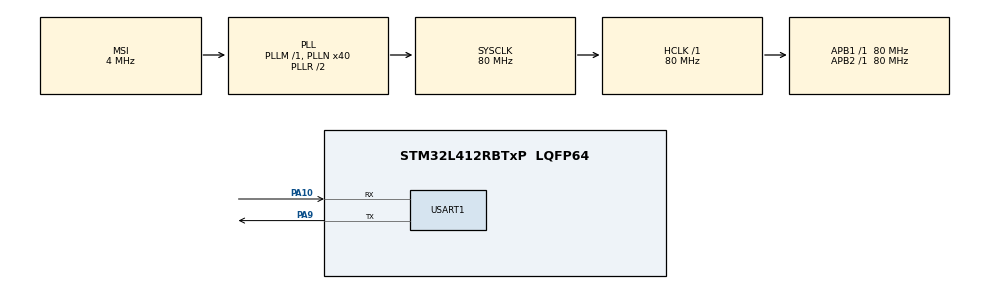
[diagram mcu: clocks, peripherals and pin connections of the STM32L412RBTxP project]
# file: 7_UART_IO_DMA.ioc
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Dma.Request0=USART1_RX
Dma.USART1_RX.0.Direction=DMA_PERIPH_TO_MEMORY
Dma.USART1_RX.0.Instance=DMA1_Channel5
Dma.USART1_RX.0.MemDataAlignment=DMA_MDATAALIGN_BYTE
Dma.USART1_RX.0.MemInc=DMA_MINC_ENABLE
Dma.USART1_RX.0.Mode=DMA_CIRCULAR
Dma.USART1_RX.0.PeriphDataAlignment=DMA_PDATAALIGN_BYTE
Dma.USART1_RX.0.PeriphInc=DMA_PINC_DISABLE
Dma.USART1_RX.0.Priority=DMA_PRIORITY_LOW
Mcu.Family=STM32L4
Mcu.Name=STM32L412RBTxP
Mcu.Package=LQFP64
NVIC.DMA1_Channel5_IRQn=true\:0\:0\:false\:false\:true\:false\:true
NVIC.PriorityGroup=NVIC_PRIORITYGROUP_4
NVIC.USART1_IRQn=true\:0\:0\:false\:false\:true\:true\:true
PA10.Mode=Asynchronous
PA10.Signal=USART1_RX
PA9.Mode=Asynchronous
PA9.Signal=USART1_TX
ProjectManager.HeapSize=0x200
ProjectManager.StackSize=0x400
ProjectManager.TargetToolchain=STM32CubeIDE
RCC.ADCFreq_Value=80000000
RCC.AHBFreq_Value=80000000
RCC.APB1Freq_Value=80000000
RCC.APB1TimFreq_Value=80000000
RCC.APB2Freq_Value=80000000
RCC.APB2TimFreq_Value=80000000
RCC.CortexFreq_Value=80000000
RCC.HCLKFreq_Value=80000000
RCC.HSE_VALUE=8000000
RCC.HSI48_VALUE=48000000
RCC.HSI_VALUE=16000000
RCC.LSE_VALUE=32768
RCC.MSI_VALUE=4000000
RCC.PLLN=40
RCC.SYSCLKFreq_VALUE=80000000
RCC.SYSCLKSource=RCC_SYSCLKSOURCE_PLLCLK
RCC.USBFreq_Value=4000000
RCC.VCOOutputFreq_Value=160000000
USART1.VirtualMode-Asynchronous=VM_ASYNC
board=custom

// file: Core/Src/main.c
/* USER CODE BEGIN Header */
/**
  ******************************************************************************
  * @file           : main.c
  * @brief          : Main program body
  ******************************************************************************
  * @attention
  *
  * <h2><center>&copy; Copyright (c) 2021 STMicroelectronics.
  * All rights reserved.</center></h2>
  *
  * This software component is licensed by ST under BSD 3-Clause license,
  * the "License"; You may not use this file except in compliance with the
  * License. You may obtain a copy of the License at:
  *                        opensource.org/licenses/BSD-3-Clause
  *
  ******************************************************************************
  */
/* USER CODE END Header */
#include "main.h"
#include "dma.h"
#include "usart.h"
#include "gpio.h"

/* USER CODE BEGIN Includes */
#include <string.h>
/* USER CODE END Includes */

/* USER CODE BEGIN PV */
#if 0
#define DMA_BUF_SIZE 100
uint8_t rx_dma_buf[DMA_BUF_SIZE];
#define get_dma_data_length() huart1.hdmarx->Instance->CNDTR
#define get_dma_total_size()  huart1.RxXferSize
#else
uint8_t rxBuffer[10];

#endif
/* USER CODE END PV */

void SystemClock_Config(void);

/* USER CODE BEGIN 0 */
#if 0
void uart_rx_dma_handler(){
    /* buffer index*/
    static uint32_t old_pos=0;
    uint32_t pos;

    /* trans buffer from dma buffer*/
    uint8_t rx_buf[DMA_BUF_SIZE];
    uint32_t rx_size = 0;

    /*trans variable*/
    uint8_t ch;
    uint8_t i;

    /*find current index in buffer*/
    pos = get_dma_total_size() - get_dma_data_length();

    if(pos != old_pos)
    {
        if(pos > old_pos)
        {
            /* get data from dma buf*/
            memcpy(rx_buf, &rx_dma_buf[old_pos], pos - old_pos);
            rx_size += pos - old_pos;
        }
        else
        {
            /* Overflow */
            /* fisrt get data until end index */
            memcpy(rx_buf, &rx_dma_buf[old_pos], get_dma_total_size() - old_pos);
            rx_size += get_dma_total_size() - old_pos;

            /* check cur and get data until cur index*/
            if(pos > 0)
            {
                memcpy(&rx_buf[get_dma_total_size() - old_pos], &rx_dma_buf[0], pos);
                rx_size += pos;
            }
        }

        old_pos = pos;
        if(rx_size > 0)
        {
            for(i = 0;i<rx_size;i++)
            {
                ch = rx_buf[i];
                //printf("%02X", ch);
                HAL_UART_Transmit(&huart1, &ch, sizeof(uint8_t), 1000);
            }
            //printf("\n\r");
        }
    }
}
#else
void HAL_UART_RxCpltCallback(UART_HandleTypeDef *huart)
{
  HAL_UART_Transmit(&huart1, rxBuffer, 10, 0xFFFF);
}

#endif
/* USER CODE END 0 */

int main(void)
{

  /* MCU Configuration--------------------------------------------------------*/

  /* Reset of all peripherals, Initializes the Flash interface and the Systick. */
  HAL_Init();

  /* Configure the system clock */
  SystemClock_Config();

  /* Initialize all configured peripherals */
  MX_GPIO_Init();
  MX_DMA_Init();
  MX_USART1_UART_Init();
  /* USER CODE BEGIN 2 */
#if 0
  HAL_UART_Receive_DMA(&huart1, rx_dma_buf, DMA_BUF_SIZE);
#else
  HAL_UART_Receive_DMA(&huart1, rxBuffer, 10);
#endif
  /* USER CODE END 2 */

  /* Infinite loop */
  /* USER CODE BEGIN WHILE */
  while (1)
  {
#if 0
    uart_rx_dma_handler();
#else

#endif
    /* USER CODE END WHILE */

  }
}

void SystemClock_Config(void)
{
  RCC_OscInitTypeDef RCC_OscInitStruct = {0};
  RCC_ClkInitTypeDef RCC_ClkInitStruct = {0};
  RCC_PeriphCLKInitTypeDef PeriphClkInit = {0};

  /** Configure the main internal regulator output voltage
  */
  if (HAL_PWREx_ControlVoltageScaling(PWR_REGULATOR_VOLTAGE_SCALE1) != HAL_OK)
  {
    Error_Handler();
  }
  /** Initializes the RCC Oscillators according to the specified parameters
  * in the RCC_OscInitTypeDef structure.
  */
  RCC_OscInitStruct.OscillatorType = RCC_OSCILLATORTYPE_MSI;
  RCC_OscInitStruct.MSIState = RCC_MSI_ON;
  RCC_OscInitStruct.MSICalibrationValue = 0;
  RCC_OscInitStruct.MSIClockRange = RCC_MSIRANGE_6;
  RCC_OscInitStruct.PLL.PLLState = RCC_PLL_ON;
  RCC_OscInitStruct.PLL.PLLSource = RCC_PLLSOURCE_MSI;
  RCC_OscInitStruct.PLL.PLLM = 1;
  RCC_OscInitStruct.PLL.PLLN = 40;
  RCC_OscInitStruct.PLL.PLLQ = RCC_PLLQ_DIV2;
  RCC_OscInitStruct.PLL.PLLR = RCC_PLLR_DIV2;
  if (HAL_RCC_OscConfig(&RCC_OscInitStruct) != HAL_OK)
  {
    Error_Handler();
  }
  /** Initializes the CPU, AHB and APB buses clocks
  */
  RCC_ClkInitStruct.ClockType = RCC_CLOCKTYPE_HCLK|RCC_CLOCKTYPE_SYSCLK
                              |RCC_CLOCKTYPE_PCLK1|RCC_CLOCKTYPE_PCLK2;
  RCC_ClkInitStruct.SYSCLKSource = RCC_SYSCLKSOURCE_PLLCLK;
  RCC_ClkInitStruct.AHBCLKDivider = RCC_SYSCLK_DIV1;
  RCC_ClkInitStruct.APB1CLKDivider = RCC_HCLK_DIV1;
  RCC_ClkInitStruct.APB2CLKDivider = RCC_HCLK_DIV1;

  if (HAL_RCC_ClockConfig(&RCC_ClkInitStruct, FLASH_LATENCY_4) != HAL_OK)
  {
    Error_Handler();
  }
  PeriphClkInit.PeriphClockSelection = RCC_PERIPHCLK_USART1;
  PeriphClkInit.Usart1ClockSelection = RCC_USART1CLKSOURCE_PCLK2;
  if (HAL_RCCEx_PeriphCLKConfig(&PeriphClkInit) != HAL_OK)
  {
    Error_Handler();
  }
}

void Error_Handler(void)
{
  __disable_irq();
  while (1)
  {
  }
}

/************************ (C) COPYRIGHT STMicroelectronics *****END OF FILE****/
